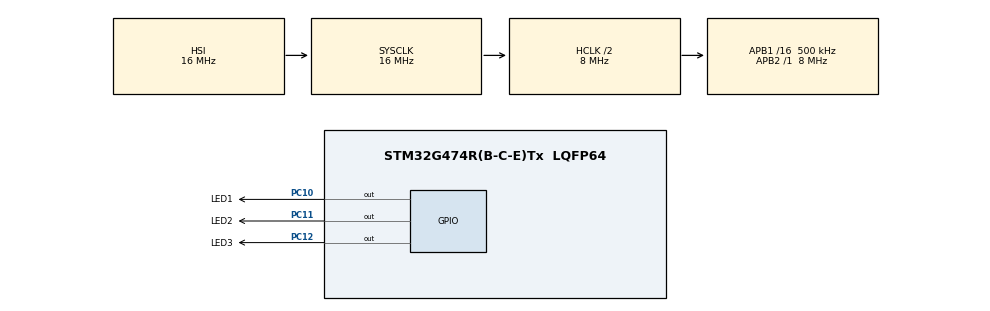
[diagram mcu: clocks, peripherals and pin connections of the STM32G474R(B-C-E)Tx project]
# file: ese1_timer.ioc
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Mcu.Family=STM32G4
Mcu.Name=STM32G474R(B-C-E)Tx
Mcu.Package=LQFP64
NVIC.PriorityGroup=NVIC_PRIORITYGROUP_4
NVIC.TIM2_IRQn=true\:0\:0\:false\:false\:true\:true\:true\:true
NVIC.TIM6_DAC_IRQn=true\:0\:0\:false\:false\:true\:true\:true\:true
NVIC.TIM7_DAC_IRQn=true\:0\:0\:false\:false\:true\:true\:true\:true
PC10.GPIO_Label=LED1
PC10.Signal=GPIO_Output
PC11.GPIO_Label=LED2
PC11.Signal=GPIO_Output
PC12.GPIO_Label=LED3
PC12.Signal=GPIO_Output
ProjectManager.HeapSize=0x200
ProjectManager.StackSize=0x400
ProjectManager.TargetToolchain=STM32CubeIDE
RCC.AHBCLKDivider=RCC_SYSCLK_DIV2
RCC.AHBFreq_Value=8000000
RCC.APB1CLKDivider=RCC_HCLK_DIV16
RCC.APB1Freq_Value=500000
RCC.APB1TimFreq_Value=1000000
RCC.APB2Freq_Value=8000000
RCC.APB2TimFreq_Value=8000000
RCC.CortexFreq_Value=8000000
RCC.EXTERNAL_CLOCK_VALUE=12288000
RCC.HCLKFreq_Value=8000000
RCC.HSE_VALUE=8000000
RCC.HSI48_VALUE=48000000
RCC.HSI_VALUE=16000000
RCC.LSE_VALUE=32768
RCC.SYSCLKFreq_VALUE=16000000
RCC.USBFreq_Value=64000000
RCC.VCOOutputFreq_Value=128000000
TIM2.PeriodNoDither=124
TIM2.Prescaler=999
TIM6.PeriodNoDither=249
TIM6.Prescaler=999
TIM7.PeriodNoDither=499
TIM7.Prescaler=999
VP_SYS_VS_DBSignals.Mode=DisableDeadBatterySignals
VP_TIM2_VS_ClockSourceINT.Mode=Internal
VP_TIM6_VS_ClockSourceINT.Mode=Enable_Timer
VP_TIM7_VS_ClockSourceINT.Mode=Enable_Timer
board=custom

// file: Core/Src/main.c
/* USER CODE BEGIN Header */
/**
  ******************************************************************************
  * @file           : main.c
  * @brief          : Main program body
  ******************************************************************************
  * @attention
  *
  * Copyright (c) 2026 STMicroelectronics.
  * All rights reserved.
  *
  * This software is licensed under terms that can be found in the LICENSE file
  * in the root directory of this software component.
  * If no LICENSE file comes with this software, it is provided AS-IS.
  *
  ******************************************************************************
  */
/* USER CODE END Header */
#include "main.h"
#include "tim.h"
#include "gpio.h"

void SystemClock_Config(void);

int main(void)
{

  /* MCU Configuration--------------------------------------------------------*/

  /* Reset of all peripherals, Initializes the Flash interface and the Systick. */
  HAL_Init();

  /* Configure the system clock */
  SystemClock_Config();

  /* Initialize all configured peripherals */
  MX_GPIO_Init();
  MX_TIM2_Init();
  MX_TIM6_Init();
  MX_TIM7_Init();
  /* USER CODE BEGIN 2 */
  HAL_TIM_Base_Start_IT(&htim2);
  HAL_TIM_Base_Start_IT(&htim6);
  HAL_TIM_Base_Start_IT(&htim7);
  /* USER CODE END 2 */

  /* Infinite loop */
  while (1)
  {

  }
}

void SystemClock_Config(void)
{
  RCC_OscInitTypeDef RCC_OscInitStruct = {0};
  RCC_ClkInitTypeDef RCC_ClkInitStruct = {0};

  /** Configure the main internal regulator output voltage
  */
  HAL_PWREx_ControlVoltageScaling(PWR_REGULATOR_VOLTAGE_SCALE1);

  /** Initializes the RCC Oscillators according to the specified parameters
  * in the RCC_OscInitTypeDef structure.
  */
  RCC_OscInitStruct.OscillatorType = RCC_OSCILLATORTYPE_HSI;
  RCC_OscInitStruct.HSIState = RCC_HSI_ON;
  RCC_OscInitStruct.HSICalibrationValue = RCC_HSICALIBRATION_DEFAULT;
  RCC_OscInitStruct.PLL.PLLState = RCC_PLL_NONE;
  if (HAL_RCC_OscConfig(&RCC_OscInitStruct) != HAL_OK)
  {
    Error_Handler();
  }

  /** Initializes the CPU, AHB and APB buses clocks
  */
  RCC_ClkInitStruct.ClockType = RCC_CLOCKTYPE_HCLK|RCC_CLOCKTYPE_SYSCLK
                              |RCC_CLOCKTYPE_PCLK1|RCC_CLOCKTYPE_PCLK2;
  RCC_ClkInitStruct.SYSCLKSource = RCC_SYSCLKSOURCE_HSI;
  RCC_ClkInitStruct.AHBCLKDivider = RCC_SYSCLK_DIV2;
  RCC_ClkInitStruct.APB1CLKDivider = RCC_HCLK_DIV16;
  RCC_ClkInitStruct.APB2CLKDivider = RCC_HCLK_DIV1;

  if (HAL_RCC_ClockConfig(&RCC_ClkInitStruct, FLASH_LATENCY_0) != HAL_OK)
  {
    Error_Handler();
  }
}

void Error_Handler(void)
{
  __disable_irq();
  while (1)
  {
  }
}
